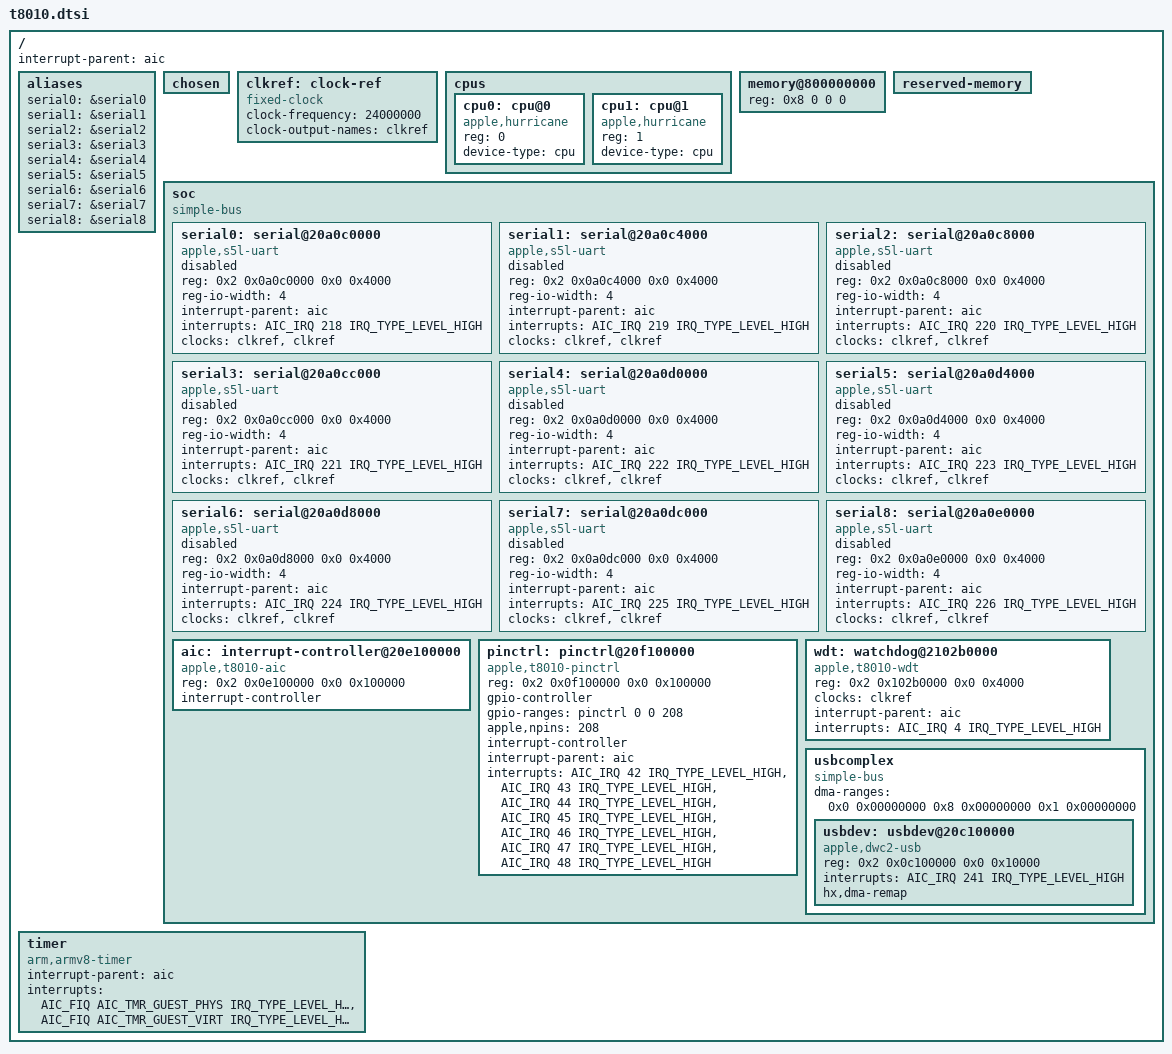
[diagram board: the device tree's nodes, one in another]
// SPDX-License-Identifier: GPL-2.0+ OR MIT
/*
 * Apple T8010 "A10" SoC
 *
 * Copyright (c) 2022, Konrad Dybcio <konrad.dybcio@somainline.org>
 * Based on Asahi Linux's M1 (t8103.dtsi) and Corellium's A10 efforts.
 */

#include <dt-bindings/gpio/gpio.h>
#include <dt-bindings/interrupt-controller/apple-aic.h>
#include <dt-bindings/interrupt-controller/irq.h>
#include <dt-bindings/pinctrl/apple.h>

/ {
	interrupt-parent = <&aic>;
	#address-cells = <2>;
	#size-cells = <2>;

	aliases {
		serial0 = &serial0;
		serial1 = &serial1;
		serial2 = &serial2;
		serial3 = &serial3;
		serial4 = &serial4;
		serial5 = &serial5;
		serial6 = &serial6;
		serial7 = &serial7;
		serial8 = &serial8;
	};

	chosen {
		#address-cells = <2>;
		#size-cells = <2>;
		ranges;
	};

	clkref: clock-ref {
		compatible = "fixed-clock";
		#clock-cells = <0>;
		clock-frequency = <24000000>;
		clock-output-names = "clkref";
	};

	cpus {
		#address-cells = <1>;
		#size-cells = <0>;

		cpu0: cpu@0 {
			compatible = "apple,hurricane";
			reg = <0>;
			device-type = "cpu";
		};

		cpu1: cpu@1 {
			compatible = "apple,hurricane";
			reg = <1>;
			device-type = "cpu";
		};
	};

	memory@800000000 {
		device_type = "memory";
		/* To be filled in by the bootloader (based on XNU BootArgs). */
		reg = <0x8 0 0 0>;
	};

	reserved-memory {
		#address-cells = <2>;
		#size-cells = <2>;
		ranges;

		/*
		 * The bootloader reserves a region for the (varying-address, depending
		 * on what FW your device runs AND model) framebuffer under this node.
		 */
	};

	soc {
		compatible = "simple-bus";
		#address-cells = <2>;
		#size-cells = <2>;
		ranges;

		serial0: serial@20a0c0000 {
			compatible = "apple,s5l-uart";
			reg = <0x2 0x0a0c0000 0x0 0x4000>;
			reg-io-width = <4>;
			interrupt-parent = <&aic>;
			interrupts = <AIC_IRQ 218 IRQ_TYPE_LEVEL_HIGH>;
			/* Use the bootloader-enabled clocks for now. */
			clocks = <&clkref>, <&clkref>;
			clock-names = "uart", "clk_uart_baud0";
			status = "disabled";
		};

		serial1: serial@20a0c4000 {
			compatible = "apple,s5l-uart";
			reg = <0x2 0x0a0c4000 0x0 0x4000>;
			reg-io-width = <4>;
			interrupt-parent = <&aic>;
			interrupts = <AIC_IRQ 219 IRQ_TYPE_LEVEL_HIGH>;
			/* Use the bootloader-enabled clocks for now. */
			clocks = <&clkref>, <&clkref>;
			clock-names = "uart", "clk_uart_baud0";
			status = "disabled";
		};

		serial2: serial@20a0c8000 {
			compatible = "apple,s5l-uart";
			reg = <0x2 0x0a0c8000 0x0 0x4000>;
			reg-io-width = <4>;
			interrupt-parent = <&aic>;
			interrupts = <AIC_IRQ 220 IRQ_TYPE_LEVEL_HIGH>;
			/* Use the bootloader-enabled clocks for now. */
			clocks = <&clkref>, <&clkref>;
			clock-names = "uart", "clk_uart_baud0";
			status = "disabled";
		};

		serial3: serial@20a0cc000 {
			compatible = "apple,s5l-uart";
			reg = <0x2 0x0a0cc000 0x0 0x4000>;
			reg-io-width = <4>;
			interrupt-parent = <&aic>;
			interrupts = <AIC_IRQ 221 IRQ_TYPE_LEVEL_HIGH>;
			/* Use the bootloader-enabled clocks for now. */
			clocks = <&clkref>, <&clkref>;
			clock-names = "uart", "clk_uart_baud0";
			status = "disabled";
		};

		serial4: serial@20a0d0000 {
			compatible = "apple,s5l-uart";
			reg = <0x2 0x0a0d0000 0x0 0x4000>;
			reg-io-width = <4>;
			interrupt-parent = <&aic>;
			interrupts = <AIC_IRQ 222 IRQ_TYPE_LEVEL_HIGH>;
			/* Use the bootloader-enabled clocks for now. */
			clocks = <&clkref>, <&clkref>;
			clock-names = "uart", "clk_uart_baud0";
			status = "disabled";
		};

		serial5: serial@20a0d4000 {
			compatible = "apple,s5l-uart";
			reg = <0x2 0x0a0d4000 0x0 0x4000>;
			reg-io-width = <4>;
			interrupt-parent = <&aic>;
			interrupts = <AIC_IRQ 223 IRQ_TYPE_LEVEL_HIGH>;
			/* Use the bootloader-enabled clocks for now. */
			clocks = <&clkref>, <&clkref>;
			clock-names = "uart", "clk_uart_baud0";
			status = "disabled";
		};

		serial6: serial@20a0d8000 {
			compatible = "apple,s5l-uart";
			reg = <0x2 0x0a0d8000 0x0 0x4000>;
			reg-io-width = <4>;
			interrupt-parent = <&aic>;
			interrupts = <AIC_IRQ 224 IRQ_TYPE_LEVEL_HIGH>;
			/* Use the bootloader-enabled clocks for now. */
			clocks = <&clkref>, <&clkref>;
			clock-names = "uart", "clk_uart_baud0";
			status = "disabled";
		};

		serial7: serial@20a0dc000 {
			compatible = "apple,s5l-uart";
			reg = <0x2 0x0a0dc000 0x0 0x4000>;
			reg-io-width = <4>;
			interrupt-parent = <&aic>;
			interrupts = <AIC_IRQ 225 IRQ_TYPE_LEVEL_HIGH>;
			/* Use the bootloader-enabled clocks for now. */
			clocks = <&clkref>, <&clkref>;
			clock-names = "uart", "clk_uart_baud0";
			status = "disabled";
		};

		serial8: serial@20a0e0000 {
			compatible = "apple,s5l-uart";
			reg = <0x2 0x0a0e0000 0x0 0x4000>;
			reg-io-width = <4>;
			interrupt-parent = <&aic>;
			interrupts = <AIC_IRQ 226 IRQ_TYPE_LEVEL_HIGH>;
			/* Use the bootloader-enabled clocks for now. */
			clocks = <&clkref>, <&clkref>;
			clock-names = "uart", "clk_uart_baud0";
			status = "disabled";
		};

		aic: interrupt-controller@20e100000 {
			compatible = "apple,t8010-aic", "apple,s5l8960x-aic", "apple,aic";
			reg = <0x2 0x0e100000 0x0 0x100000>;
			#interrupt-cells = <3>;
			interrupt-controller;
		};

		pinctrl: pinctrl@20f100000 {
			compatible = "apple,t8010-pinctrl", "apple,pinctrl";
			reg = <0x2 0x0f100000 0x0 0x100000>;

			gpio-controller;
			#gpio-cells = <2>;
			gpio-ranges = <&pinctrl 0 0 208>;
			apple,npins = <208>;

			interrupt-controller;
			#interrupt-cells = <2>;
			interrupt-parent = <&aic>;
			interrupts = <AIC_IRQ 42 IRQ_TYPE_LEVEL_HIGH>,
				     <AIC_IRQ 43 IRQ_TYPE_LEVEL_HIGH>,
				     <AIC_IRQ 44 IRQ_TYPE_LEVEL_HIGH>,
				     <AIC_IRQ 45 IRQ_TYPE_LEVEL_HIGH>,
				     <AIC_IRQ 46 IRQ_TYPE_LEVEL_HIGH>,
				     <AIC_IRQ 47 IRQ_TYPE_LEVEL_HIGH>,
				     <AIC_IRQ 48 IRQ_TYPE_LEVEL_HIGH>;
		};

		wdt: watchdog@2102b0000 {
			compatible = "apple,t8010-wdt", "apple,wdt";
			reg = <0x2 0x102b0000 0x0 0x4000>;
			clocks = <&clkref>;
			interrupt-parent = <&aic>;
			interrupts = <AIC_IRQ 4 IRQ_TYPE_LEVEL_HIGH>;
		};

		usbcomplex {
			compatible = "simple-bus";
			#address-cells = <2>;
			#size-cells = <2>;
			dma-ranges = <0x0 0x00000000 0x8 0x00000000 0x1 0x00000000>;
			ranges;

			usbdev: usbdev@20c100000 {
				compatible = "apple,dwc2-usb";
				reg = <0x2 0x0c100000 0x0 0x10000>;
				interrupts = <AIC_IRQ 241 IRQ_TYPE_LEVEL_HIGH>;
				hx,dma-remap;
			};
		};
	};

	timer {
		compatible = "arm,armv8-timer";
		interrupt-parent = <&aic>;
		interrupt-names = "phys", "virt";
		/* Note that A10 doesn't actually have a hypervisor (EL2 is not implemented). */
		interrupts = <AIC_FIQ AIC_TMR_GUEST_PHYS IRQ_TYPE_LEVEL_HIGH>,
			     <AIC_FIQ AIC_TMR_GUEST_VIRT IRQ_TYPE_LEVEL_HIGH>;
	};
};
